# SAMA7D65D2GN8 register map
Vendor: Microchip Technology; Series: SAMA7D6; File version: 0
Registers are 32-bit, read-write, reset 0x0 unless marked. A register's access mark holds for its fields unless they carry their own. Offsets are from the block's base; [hi:lo] are bit positions; {n}, {i} and the like mark numbered series.

## TRNG — True Random Number Generator
Base 0xE160C000
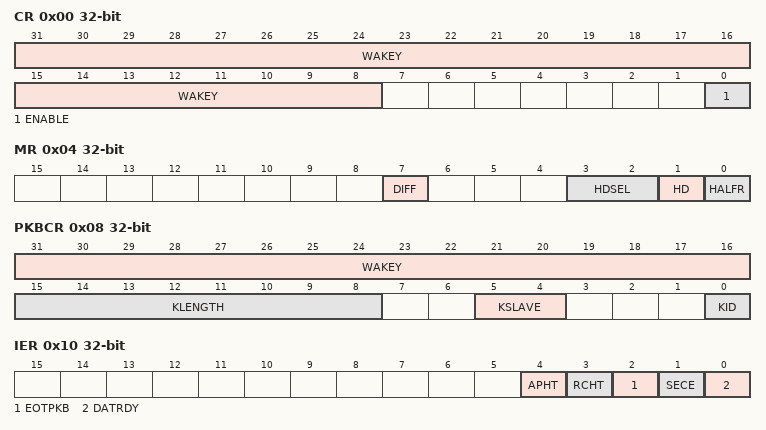
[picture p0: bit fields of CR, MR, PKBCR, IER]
0x00 CR wo — Control Register
  [31:8] WAKEY — Register Write Access Key
    0x524E47=PASSWD (Writing any other value in this field aborts the write operation.)
  [0] ENABLE — Enable TRNG to Provide Random Values
    0=Disables the TRNG if 0x524E47 ('RNG' in ASCII) is written in WAKEY field at the same time; 1=Enables the TRNG if 0x524E47 ('RNG' in ASCII) is written in WAKEY field at the same time
0x04 MR — Mode Register
  [7] DIFF — Minimum Hamming Distance
    0=DISABLED (Delivers a new random sample without condition with the previous sample (unless HD=1).)
  [3:2] HDSEL — Hamming Distance Selection
    0=TWO (Two consecutive random samples have a minimum Hamming distance of 2.); 1=FOUR (Two consecutive random samples have a minimum Hamming distance of 4.); 2=EIGHT (Two consecutive random samples have a minimum Hamming distance of 8.); 3=SIXTEEN (Two consecutive random samples have a minimum Hamming distance of 16.)
  [1] HD
  [0] HALFR — Half Rate Enable
    0=DISABLED (Maximum stream rate provided (1 sample every 84 MCK clock cycles).); 1=ENABLED (Half maximum stream rate provided if the peripheral clock frequency is above 100 MHz (1 sample every 168 MCK clock cycles).)
0x08 PKBCR wo — Private Key Bus Control Register
  [31:16] WAKEY — Register Write Access Key
    0x524B=PASSWD (Writing any other value in this field aborts the write operation.)
  [15:8] KLENGTH — Key Length
  [5:4] KSLAVE — Key Bus Client
    0=TDES_ID; 1=AES_ID; 2=TZAESB_ID; 3=OTPC_ID
  [0] KID — Key ID
    0=SECURE_KEY (TrustZone Secure Key access.); 1=NOT_SECURE_KEY (TrustZone Not Secure Key access.)
0x10 IER wo — Interrupt Enable Register
  [all] fields
    0=No effect; 1=Enables the corresponding interrupt
  [4] APHT — Adaptive Proportional Health Test Failure Detection (cleared on read)
  [3] RCHT — Repetitive Count Health Test Failure Detection (cleared on read)
  [2] EOTPKB — End Of Transfer on Private Key Bus Interrupt Enable
  [1] SECE — Security and/or Safety Event Interrupt Enable
  [0] DATRDY — Data Ready Interrupt Enable
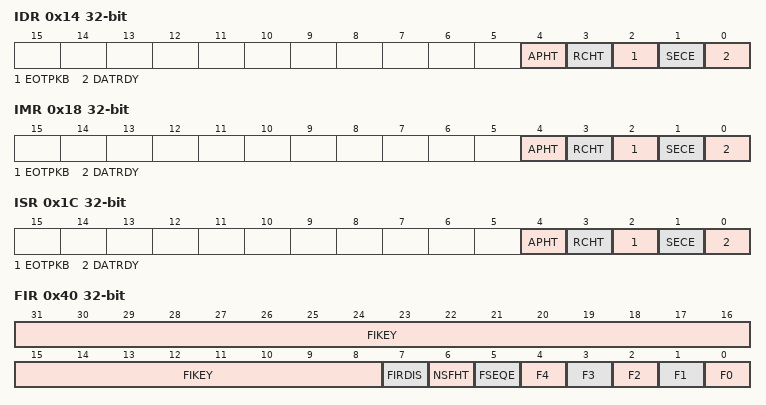
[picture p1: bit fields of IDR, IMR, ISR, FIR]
0x14 IDR wo — Interrupt Disable Register
  [all] fields
    0=No effect; 1=Disables the corresponding interrupt
  [4] APHT — Adaptive Proportional Health Test Failure Detection (cleared on read)
  [3] RCHT — Repetitive Count Health Test Failure Detection (cleared on read)
  [2] EOTPKB — End Of Transfer on Private Key Bus Interrupt Disable
  [1] SECE — Security and/or Safety Event Interrupt Disable
  [0] DATRDY — Data Ready Interrupt Disable
0x18 IMR ro — Interrupt Mask Register
  [all] fields
    0=The corresponding interrupt is not enabled; 1=The corresponding interrupt is enabled
  [4] APHT — Adaptive Proportional Health Test Failure Detection (cleared on read)
  [3] RCHT — Repetitive Count Health Test Failure Detection (cleared on read)
  [2] EOTPKB — End Of Transfer on Private Key Bus Interrupt Mask
  [1] SECE — Security and/or Safety Event Interrupt Mask
  [0] DATRDY — Data Ready Interrupt Mask
0x1C ISR ro — Interrupt Status Register
  [4] APHT — Adaptive Proportional Health Test Failure Detection (cleared on read)
    0=No loss of entropy detected in the TRNG noise source since the last read of the Interrupt Status register; 1=A significant loss of entropy has been detected in the TRNG noise source since the last read of the Interrupt Status register
  [3] RCHT — Repetitive Count Health Test Failure Detection (cleared on read)
    0=No important failure detected in the TRNG noise source since the last read of the Interrupt Status register; 1=An important failure has been detected in the TRNG noise source since the last read of the Interrupt Status register
  [2] EOTPKB — End Of Transfer on Private Key Bus (cleared on read)
    0=No private key bus transfer has ended since the last read of the Interrupt Status register; 1=The private key bus transfer has ended
  [1] SECE — Security and/or Safety Event (cleared on read)
    0=No safety or security event occurred since the last read of the Interrupt Status Register; 1=One or more safety or security event occurred since the last read of TRNG_ISR. For details on the event, see TRNG Write Protection Status Register.
  [0] DATRDY — Data Ready (cleared on read or when TRNG_ODATA is read)
    0=Output data is not valid or TRNG is disabled; 1=New random value has been completed since the last read of TRNG_ISR or TRNG_ODATA
0x30 HTMR reset 0x1000000 — Health Test Mode Register
  [25:16] THRESHOLD — Failure Detection Threshold for SP800-90B Adaptive Proportion Test
0x40 FIR — Fault Injection Register
  [31:8] FIKEY — Fault Injection Access Key
    0x544649=PASSWD (Writing any other value in this field aborts the write operation.)
  [7] FIRDIS — Fault Injection Register Disable
    0=NO_EFFECT; 1=ACTIVE (Disables the fault injection until the next hardware reset. The command is valid only if the TRNG_WPSR.SEQE=0 and the other bits are cleared (F0=F1=F2=F3=F4=FSEQE=NSFHT=0).)
  [6] NSFHT — Noise Source Failure for Health Test
    0=NONE (No effect.); 1=FAIL (Injects a fault on the noise source (if TRNG_CR.ENABLE=1, TRNG_ISR.RCHT=0 and TRNG_ISR.APHT=0) for a period that ends automatically as soon as TRNG_ISR.APHT=1 and TRNG_ISR.RCHT=1. For security reasons, when FIRLCK=1, writing NSFHT=1 has no effect.)
  [5] FSEQE — Single Fault for TRNG_MR
    0=NO_EFFECT; 1=INJECT_CLEAR (Injects a single fault on TRNG_MR if the TRNG is disabled (for security reasons). As a consequence, the flag TRNG_WPSR.SEQE raises and the flag TRNG_ISR.SECE=1. Clears the fault if it has been previously injected.)
  [4] F4 — Single Fault for TRNG Interrupt Mask Bit (TRNG_IMR.DATRDY)
    0=Clears the fault. The flag TRNG_WPSR.SDEE is automatically cleared.; 1=Injects a single fault on the reinforced safety for the TRNG_IMR.WPCREN bit if 0x544649 ('TFI' in ASCII) is written in the FIKEY field at the same time. The TRNG remains in the same state, the flag TRNG_ISR.SECE=1 and the flag TRNG_WPSR.SDEE=1.
  [3] F3 — Single Fault for TRNG Write Protection Bit (TRNG_WPMR.WPCREN)
    0=Clears the fault. The flag TRNG_WPSR.SDEE is automatically cleared if no other fault exists.; 1=Injects a single fault on the reinforced safety for the TRNG_WPMR.WPEN bit if 0x544649 ('TFI' in ASCII) is written in the FIKEY field at the same time. The TRNG Control register remains protected, the flag TRNG_ISR.SECE=1 and the flag TRNG_WPSR.SDEE=1.
  [2] F2 — Single Fault for TRNG Write Protection Bit (TRNG_WPMR.WPITEN)
    0=Clears the fault. The flag TRNG_WPSR.SDEE is automatically cleared if no other fault exists.; 1=Injects a single fault on the reinforced safety for the TRNG_WPMR.WPITEN bit if 0x544649 ('TFI' in ASCII) is written in the FIKEY field at the same time. The TRNG protection remains active for interrupt registers, the flag TRNG_ISR.SECE=1 and the flag TRNG_WPSR.SDEE=1.
  [1] F1 — Single Fault for TRNG Write Protection Bit (TRNG_WPMR.WPEN)
    0=Clears the fault. The flag TRNG_WPSR.SDEE is automatically cleared if no other fault exists.; 1=Injects a single fault on the reinforced safety for the TRNG_WPMR.WPEN bit if 0x544649 ('TFI' in ASCII) is written in the FIKEY field at the same time. The TRNG protection remains active for Mode registers, the flag TRNG_ISR.SECE=1 and the flag TRNG_WPSR.SDEE=1.
  [0] F0 — Single Fault for TRNG Enable Bit (TRNG_CR.ENABLE)
    0=Clears the fault. The flag TRNG_WPSR.SDEE is automatically cleared.; 1=Injects a single fault on the reinforced safety for the TRNG_CR.ENABLE bit if 0x544649 ('TFI' in ASCII) is written in the FIKEY field at the same time. The TRNG remains in the same state, the flag TRNG_ISR.SECE=1 and the flag TRNG_WPSR.SDEE=1.
0x50 ODATA ro — Output Data Register
  [31:0] ODATA — Output Data
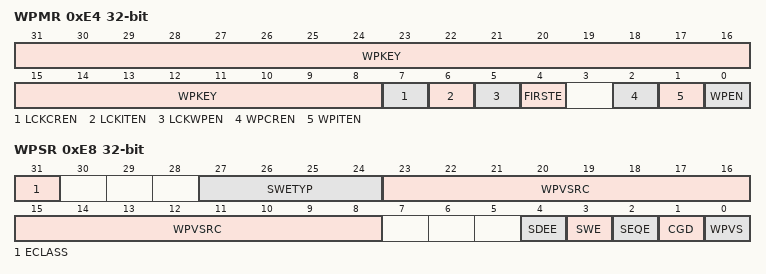
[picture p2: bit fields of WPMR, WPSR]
0xE4 WPMR — Write Protection Mode Register
  [31:8] WPKEY — Write Protection Key
    0x524E47=PASSWD (Writing any other value in this field aborts the write operation of bits WPEN, WPITEN and WPCREN. Always reads as 0.)
  [7] LCKCREN — Write Protection Lock Enable for Control Registers
    0=No effect
  [6] LCKITEN — Write Protection Lock Enable for Interrupt Register
    0=No effect
  [5] LCKWPEN — Write Protection Lock Enable for Configuration Register
    0=No effect
  [4] FIRSTE — First Error Report Enable
    0=The last write protection violation source is reported in TRNG_WPSR.WPVSRC and the last software control error type is reported in TRNG_WPSR.SWETYP. The TRNG_ISR.SECE flag is set at the first error occurrence within a series.; 1=Only the first write protection violation source is reported in TRNG_WPSR.WPVSRC and only the first software control error type is reported in TRNG_WPSR.SWETYP. The TRNG_ISR.SECE flag is set at the first error occurrence within a series.
  [2] WPCREN — Write Protection Control Enable
    0=Disables the write protection on control register if WPKEY corresponds to 0x524E47 ('RNG' in ASCII); 1=Enables the write protection on control register if WPKEY corresponds to 0x524E47 ('RNG' in ASCII)
  [1] WPITEN — Write Protection Interrupt Enable
    0=Disables the write protection on interrupt registers if WPKEY corresponds to 0x524E47 ('RNG' in ASCII); 1=Enables the write protection on interrupt registers if WPKEY corresponds to 0x524E47 ('RNG' in ASCII)
  [0] WPEN — Write Protection Enable
    0=Disables the write protection if WPKEY corresponds to 0x524E47 ('RNG' in ASCII); 1=Enables the write protection if WPKEY corresponds to 0x524E47 ('RNG' in ASCII)
0xE8 WPSR ro — Write Protection Status Register
  [31] ECLASS — Software Error Class (cleared on read)
    0=WARNING (An abnormal access that does not affect system functionality.); 1=ERROR (Reading TRNG_ODATA when TRNG was disabled or TRNG used for private key bus transfer. TRNG does not provide a random value. Writing to TRNG_PKBCR while a private key bus transfer is ongoing does not launch a new private key bus transfer.)
  [27:24] SWETYP — Software Error Type (cleared on read)
    0=READ_WO (TRNG is enabled and a write-only register has been read (Warning).); 1=WRITE_RO (TRNG is enabled and a write access has been performed on a read-only register (Warning).); 2=UNDEF_RW (Access to an undefined address.); 3=TRNG_DIS (The TRNG_ODATA register was read when TRNG was disabled or TRNG used for private key bus transfer (Error).); 4=PKB_BUSY (A write access to TRNG_PKBCR has been attempted during a private key bus transfer (Error).); 5=LOCK_ERR (A write access to TRNG_WPMR has been attempted when one of the write protection bits is already locked and its corresponding lock control bit is set and the corresponding write protection bit is cleared which looks like an unlock tentative (Warning).)
  [23:8] WPVSRC — Write Protection Violation Source (cleared on read)
  [4] SDEE — Single or Dual Event Error (cleared by reconfiguring the faulty registers or by clearing the error via TRNG_FIR)
    0=No single or dual error detected in TRNG_CR.ENABLE, TRNG_WPMR{WPEN,WPITEN,WPCREN} and TRNG_IMR bits
  [3] SWE — Software Control Error (cleared on read)
    0=No software error has occurred since the last read of TRNG_WPSR; 1=A software error has occurred since the last read of TRNG_WPSR. The field SWETYP details the type of software error; the associated incorrect software access is reported in the field WPVSRC (if WPVS=0).
  [2] SEQE — Internal Sequencer Error (cleared on read)
    0=No peripheral internal sequencer error has occurred since the last read of TRNG_WPSR; 1=A peripheral internal sequencer error has occurred since the last read of TRNG_WPSR. This flag is set under abnormal operating conditions.
  [1] CGD — Clock Glitch Detected (cleared on read)
    0=The clock monitoring circuitry has not been corrupted since the last read of TRNG_WPSR. Under normal operating conditions, this bit is always cleared.; 1=The clock monitoring circuitry has been corrupted since the last read of TRNG_WPSR. This flag is set in case of abnormal clock signal waveform (glitch).
  [0] WPVS — Write Protection Violation Status (cleared on read)
    0=No write protection violation has occurred since the last read of TRNG_WPSR; 1=A write protection violation has occurred since the last read of TRNG_WPSR. If this violation is an unauthorized attempt to write a protected register, the associated violation is reported into field WPVSRC.
